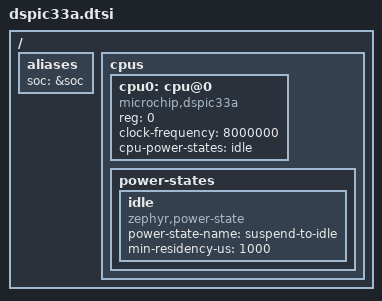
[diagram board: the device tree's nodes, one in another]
/*
 * SPDX-FileCopyrightText: Copyright (c) 2026 Microchip Technology Inc.
 * SPDX-License-Identifier: Apache-2.0
 */

/ {
	aliases {
		soc = &soc;
	};

	cpus {
		#address-cells = <1>;
		#size-cells = <0>;

		cpu0: cpu@0 {
			device_type = "cpu";
			compatible = "microchip,dspic33a";
			reg = <0>;
			clock-frequency = <8000000>;
			cpu-power-states = <&idle>;
			status = "okay";
		};

		power-states {
			idle: idle {
				compatible = "zephyr,power-state";
				power-state-name = "suspend-to-idle";
				min-residency-us = <1000>;
			};
		};
	};
};
